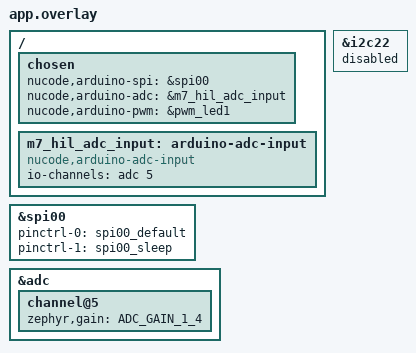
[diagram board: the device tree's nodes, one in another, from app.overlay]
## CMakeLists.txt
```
# SPDX-License-Identifier: MIT

cmake_minimum_required(VERSION 3.20.0)

find_package(Zephyr REQUIRED HINTS $ENV{ZEPHYR_BASE})
project(nucode_m7_peripheral_hil)

target_sources(app PRIVATE
  src/main.cpp
)

target_include_directories(app PRIVATE
  "${CMAKE_CURRENT_LIST_DIR}/../../../libraries/SPI/src"
)
```

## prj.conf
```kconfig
CONFIG_CPP=y
CONFIG_STD_CPP17=y
CONFIG_CPP_EXCEPTIONS=n
CONFIG_CPP_RTTI=n

CONFIG_NUCODE_ARDUINO_CORE=y
CONFIG_NUCODE_ARDUINO_RUNTIME=y
CONFIG_NUCODE_ARDUINO_API=y
CONFIG_NUCODE_ARDUINO_GPIO=n
CONFIG_NUCODE_ARDUINO_INTERRUPTS=n
CONFIG_NUCODE_ARDUINO_TIME=y
CONFIG_NUCODE_ARDUINO_SERIAL=y
CONFIG_NUCODE_ARDUINO_WIRE=n
CONFIG_NUCODE_ARDUINO_SPI=y
CONFIG_NUCODE_ARDUINO_ADC=y
CONFIG_NUCODE_ARDUINO_PWM=y

CONFIG_LOG=y
CONFIG_LOG_MODE_IMMEDIATE=y
CONFIG_SPI_LOG_LEVEL_DBG=y
CONFIG_ADC_LOG_LEVEL_DBG=y
CONFIG_PWM_LOG_LEVEL_DBG=y

CONFIG_MAIN_STACK_SIZE=4096
CONFIG_HEAP_MEM_POOL_SIZE=0
CONFIG_COMMON_LIBC_MALLOC_ARENA_SIZE=8192
```

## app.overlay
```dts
/**
 * @file app.overlay
 * @brief M7 driver HIL을 NU54DK의 실제 SPI, A0와 PWM 역할에 연결합니다.
 *
 * SPDX-License-Identifier: MIT
 */

#include <nucode/nu54dk-arduino-connectors.dtsi>
#include <nucode/nu54dk-arduino-pins.dtsi>

/ {
	chosen {
		nucode,arduino-spi = &spi00;
		nucode,arduino-adc = &m7_hil_adc_input;
		nucode,arduino-pwm = &pwm_led1;
	};

	m7_hil_adc_input: arduino-adc-input {
		compatible = "nucode,arduino-adc-input";
		io-channels = <&adc 5>;
	};
};

&spi00 {
	status = "okay";
	pinctrl-0 = <&spi00_default>;
	pinctrl-1 = <&spi00_sleep>;
	pinctrl-names = "default", "sleep";
};

/** @brief 이 SPI 전용 HIL에서 드라이버를 빌드하지 않는 보드 기본 I2C 장치를 비활성화합니다. */
&i2c22 {
	status = "disabled";
};

&adc {
	channel@5 {
		zephyr,gain = "ADC_GAIN_1_4";
	};
};
```

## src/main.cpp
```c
/**
 * @file main.cpp
 * @brief M7 실제 SPI loopback, ADC와 PWM driver 검증 결과를 UART token으로 보고합니다.
 *
 * @note 이 시험은 ADC 전압 정확도 또는 PWM 외부 파형을 검증하지 않습니다.
 *
 * SPDX-License-Identifier: MIT
 */

#include <Arduino.h>
#include <SPI.h>

#include <cstddef>
#include <cstdint>

#include "internal/AnalogBackend.h"
#include "internal/SPIBackend.h"

namespace
{
    using nucode::arduino::internal::AnalogError;
    using nucode::arduino::internal::lastAnalogDriverError;
    using nucode::arduino::internal::lastAnalogError;
    using nucode::arduino::internal::lastSpiDriverError;
    using nucode::arduino::internal::lastSpiError;
    using nucode::arduino::internal::SpiError;

    /** @brief 실제 SPI buffer chunk 경계를 통과할 loopback byte 수입니다. */
    constexpr std::size_t spi_loopback_byte_count = 40U;

    /**
	 * @brief loopback 위치마다 재현 가능한 고정 시험 byte를 생성합니다.
	 *
	 * @param index 0부터 시작하는 buffer 위치입니다.
	 * @return 해당 위치에서 송신하고 다시 수신해야 하는 byte입니다.
	 */
    constexpr std::uint8_t spiPatternByte(std::size_t index)
    {
        return static_cast<std::uint8_t>((index * 37U) + 0x5AU);
    }

    /** @brief SPI driver 실패 상태와 원본 Zephyr 오류를 UART에 기록합니다. */
    void reportSpiFailure(void)
    {
        Serial.print("NUCODE_M7_SPI_DRIVER:FAIL:error=");
        Serial.print(static_cast<unsigned int>(lastSpiError()));
        Serial.print(":driver=");
        Serial.println(lastSpiDriverError());
    }

    /** @brief ADC/PWM 실패 상태와 원본 Zephyr 오류를 UART에 기록합니다. */
    void reportAnalogFailure(const char *prefix)
    {
        Serial.print(prefix);
        Serial.print(":FAIL:error=");
        Serial.print(static_cast<unsigned int>(lastAnalogError()));
        Serial.print(":driver=");
        Serial.println(lastAnalogDriverError());
    }

    /**
	 * @brief CS 없는 실제 spi00에서 4 MHz, 40-byte 물리 loopback을 실행합니다.
	 *
	 * @return driver가 성공하고 모든 수신 byte가 송신 byte와 같으면 true입니다.
	 */
    bool testSpiLoopback(void)
    {
        std::uint8_t frame[spi_loopback_byte_count] = {};
        for (std::size_t index = 0U; index < spi_loopback_byte_count; ++index)
        {
            frame[index] = spiPatternByte(index);
        }

        SPI.begin();
        if (lastSpiError() != SpiError::none)
        {
            reportSpiFailure();
            return false;
        }

        SPI.beginTransaction(SPISettings(4000000U, MSBFIRST, SPI_MODE0));
        if (lastSpiError() != SpiError::none)
        {
            reportSpiFailure();
            return false;
        }

        SPI.transfer(frame, sizeof(frame));
        if (lastSpiError() != SpiError::none)
        {
            reportSpiFailure();
            SPI.endTransaction();
            return false;
        }

        SPI.endTransaction();
        if (lastSpiError() != SpiError::none)
        {
            reportSpiFailure();
            return false;
        }

        for (std::size_t index = 0U; index < spi_loopback_byte_count; ++index)
        {
            const std::uint8_t expected = spiPatternByte(index);
            if (frame[index] != expected)
            {
                Serial.print("NUCODE_M7_SPI_LOOPBACK:FAIL:index=");
                Serial.print(static_cast<unsigned int>(index));
                Serial.print(":expected=0x");
                Serial.print(expected, HEX);
                Serial.print(":actual=0x");
                Serial.println(frame[index], HEX);
                return false;
            }
        }

        Serial.println(
            "NUCODE_M7_SPI_LOOPBACK:PASS:frequency=4000000:bytes=40:pattern=MUL37_ADD5A");
        return true;
    }

    /**
	 * @brief 실제 A0 channel에서 12-bit raw ADC driver read를 한 번 실행합니다.
	 *
	 * @return driver가 성공하고 반환값이 0..4095이면 true입니다.
	 */
    bool testAdcDriver(void)
    {
        analogReference(AR_DEFAULT);
        if (lastAnalogError() != AnalogError::none)
        {
            reportAnalogFailure("NUCODE_M7_ADC_DRIVER");
            return false;
        }

        const int raw = analogRead(A0);
        if ((lastAnalogError() != AnalogError::none) || (raw < 0) || (raw > 4095))
        {
            reportAnalogFailure("NUCODE_M7_ADC_DRIVER");
            return false;
        }

        Serial.print("NUCODE_M7_ADC_DRIVER:PASS:raw=");
        Serial.println(raw);
        return true;
    }

    /**
	 * @brief 실제 pwm_led1에 0, 128과 255 duty driver 요청을 순서대로 전달합니다.
	 *
	 * @return 세 PWM driver 호출이 모두 성공하면 true입니다.
	 */
    bool testPwmDriver(void)
    {
        constexpr int duty_values[] = {0, 128, 255};
        for (const int duty : duty_values)
        {
            analogWrite(PIN_PWM0, duty);
            if (lastAnalogError() != AnalogError::none)
            {
                reportAnalogFailure("NUCODE_M7_PWM_DRIVER");
                return false;
            }
        }

        Serial.println("NUCODE_M7_PWM_DRIVER:PASS:duty=0,128,255");
        return true;
    }
} // namespace

/** @brief 실제 주변장치 driver 시험을 한 번 실행하고 최종 결과 token을 출력합니다. */
void setup(void)
{
    Serial.begin(115200U);
    Serial.println("NUCODE_M7_PERIPHERAL_HIL_READY");

    const bool spi_ok = testSpiLoopback();
    const bool adc_ok = testAdcDriver();
    const bool pwm_ok = testPwmDriver();
    Serial.println((spi_ok && adc_ok && pwm_ok) ? "NUCODE_M7_PERIPHERAL_HIL_PASS"
                                                : "NUCODE_M7_PERIPHERAL_HIL_FAIL");
}

/** @brief 단발성 driver 시험 뒤 추가 주변장치 접근 없이 대기합니다. */
void loop(void)
{
    delay(1000U);
}
```
